# M031AE_v1 register map
File version: 1.0
Registers are 32-bit, read-write, reset 0x0 unless marked. A register's access mark holds for its fields unless they carry their own. Offsets are from the block's base; [hi:lo] are bit positions; {n}, {i} and the like mark numbered series; 'fields as' and 'values as' point back to an identical list.

## ACMP01 — ACMP Register Map
Base 0x40045000
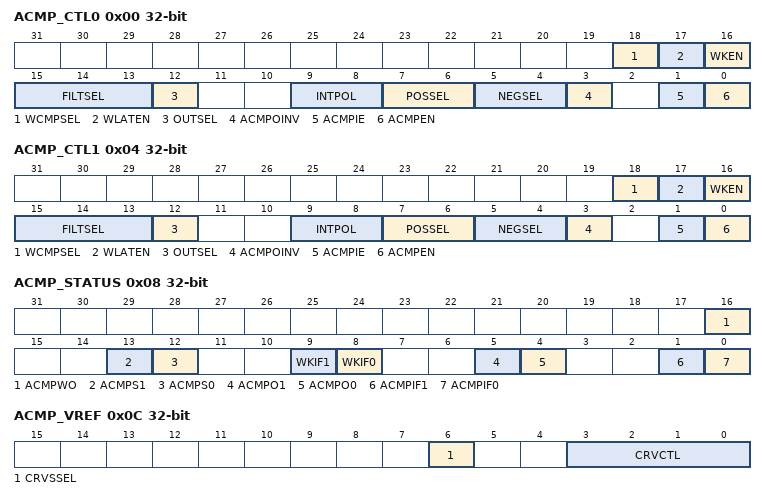
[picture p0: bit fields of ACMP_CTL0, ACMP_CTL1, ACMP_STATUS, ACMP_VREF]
0x00 ACMP_CTL0 — Analog Comparator 0 Control Register
  [18] WCMPSEL — Window Compare Mode Selection
    0=Window Compare Mode Disabled; 1=Window Compare Mode Selected
  [17] WLATEN — Window Latch Mode Enable Bit
    0=Window Latch Mode Disabled; 1=Window Latch Mode Enabled
  [16] WKEN — Power-down Wake-up Enable Bit
    0=Wake-up function Disabled; 1=Wake-up function Enabled
  [15:13] FILTSEL — Comparator Output Filter Count Selection
    0=Filter function is Disabled; 1=ACMP0 output is sampled 1 consecutive PCLK; 2=ACMP0 output is sampled 2 consecutive PCLKs; 3=ACMP0 output is sampled 4 consecutive PCLKs; 4=ACMP0 output is sampled 8 consecutive PCLKs; 5=ACMP0 output is sampled 16 consecutive PCLKs; 6=ACMP0 output is sampled 32 consecutive PCLKs; 7=ACMP0 output is sampled 64 consecutive PCLKs
  [12] OUTSEL — Comparator Output Select
    0=Comparator 0 output to ACMP0_O pin is unfiltered comparator output; 1=Comparator 0 output to ACMP0_O pin is from filter output
  [9:8] INTPOL — Interrupt Condition Polarity Selection. ACMPIF0 will be set to 1 when comparator output edge condition is detected.
    0=Rising edge or falling edge; 1=Rising edge; 2=Falling edge
  [7:6] POSSEL — Comparator Positive Input Selection
    {v}=Input from ACMP0_P{v} (v=0..3)
  [5:4] NEGSEL — Comparator Negative Input Selection
    0=ACMP0_N pin; 1=Internal comparator reference voltage (CRV); 2=Band-gap voltage
  [3] ACMPOINV — Comparator Output Inverse
    0=Comparator 0 output inverse Disabled; 1=Comparator 0 output inverse Enabled
  [1] ACMPIE — Comparator Interrupt Enable Bit
    0=Comparator 0 interrupt Disabled; 1=Comparator 0 interrupt Enabled. If WKEN (ACMP_CTL0[16]) is set to 1, the wake-up interrupt function will be enabled as well
  [0] ACMPEN — Comparator Enable Bit
    0=Comparator 0 Disabled; 1=Comparator 0 Enabled
0x04 ACMP_CTL1 — Analog Comparator 1 Control Register
  [18] WCMPSEL — Window Compare Mode Selection
    values as ACMP_CTL0.WCMPSEL
  [17] WLATEN — Window Latch Mode Enable Bit
    0=Window Latch Mode Disabled; 1=Window Latch Mode Enabled
  [16] WKEN — Power-down Wakeup Enable Bit
    0=Wake-up function Disabled; 1=Wake-up function Enabled
  [15:13] FILTSEL — Comparator Output Filter Count Selection
    0=Filter function is Disabled; 1=ACMP1 output is sampled 1 consecutive PCLK; 2=ACMP1 output is sampled 2 consecutive PCLKs; 3=ACMP1 output is sampled 4 consecutive PCLKs; 4=ACMP1 output is sampled 8 consecutive PCLKs; 5=ACMP1 output is sampled 16 consecutive PCLKs; 6=ACMP1 output is sampled 32 consecutive PCLKs; 7=ACMP1 output is sampled 64 consecutive PCLKs
  [12] OUTSEL — Comparator Output Select
    0=Comparator 1 output to ACMP1_O pin is unfiltered comparator output; 1=Comparator 1 output to ACMP1_O pin is from filter output
  [9:8] INTPOL — Interrupt Condition Polarity Selection. ACMPIF1 will be set to 1 when comparator output edge condition is detected.
    0=Rising edge or falling edge; 1=Rising edge; 2=Falling edge
  [7:6] POSSEL — Comparator Positive Input Selection
    {v}=Input from ACMP1_P{v} (v=0..3)
  [5:4] NEGSEL — Comparator Negative Input Selection
    0=ACMP1_N pin; 1=Internal comparator reference voltage (CRV); 2=Band-gap voltage
  [3] ACMPOINV — Comparator Output Inverse Control
    0=Comparator 1 output inverse Disabled; 1=Comparator 1 output inverse Enabled
  [1] ACMPIE — Comparator Interrupt Enable Bit
    0=Comparator 1 interrupt Disabled; 1=Comparator 1 interrupt Enabled. If WKEN (ACMP_CTL1[16]) is set to 1, the wake-up interrupt function will be enabled as well
  [0] ACMPEN — Comparator Enable Bit
    0=Comparator 1 Disabled; 1=Comparator 1 Enabled
0x08 ACMP_STATUS — Analog Comparator Status Register
  [16] ACMPWO — Comparator Window Output. This bit shows the output status of window compare mode
    0=The positive input voltage is outside the window; 1=The positive input voltage is in the window
  [13] ACMPS1 — Comparator 1 Status. Synchronized to the PCLK to allow reading by software. Cleared when the comparator 1 is disabled, i.e. ACMPEN (ACMP_CTL1[0]) is cleared to 0.
  [12] ACMPS0 — Comparator 0 Status. Synchronized to the PCLK to allow reading by software. Cleared when the comparator 0 is disabled, i.e. ACMPEN (ACMP_CTL0[0]) is cleared to 0.
  [9] WKIF1 — Comparator 1 Power-down Wake-up Interrupt Flag. This bit will be set to 1 when ACMP1 wake-up interrupt event occurs. Note: Write 1 to clear this bit to 0.
    0=No power-down wake-up occurred; 1=Power-down wake-up occurred
  [8] WKIF0 — Comparator 0 Power-down Wake-up Interrupt Flag. This bit will be set to 1 when ACMP0 wake-up interrupt event occurs. Note: Write 1 to clear this bit to 0.
    values as WKIF1
  [5] ACMPO1 — Comparator 1 Output. Synchronized to the PCLK to allow reading by software. Cleared when the comparator 1 is disabled, i.e. ACMPEN (ACMP_CTL1[0]) is cleared to 0.
  [4] ACMPO0 — Comparator 0 Output. Synchronized to the PCLK to allow reading by software. Cleared when the comparator 0 is disabled, i.e. ACMPEN (ACMP_CTL0[0]) is cleared to 0.
  [1] ACMPIF1 — Comparator 1 Interrupt Flag. This bit is set by hardware when the edge condition defined by INTPOL (ACMP_CTL1[9:8]) is detected on comparator 1 output. This will cause an interrupt if ACMPIE (ACMP_CTL1[1]) is set to 1. Note: Write 1 to clear this bit to 0.
  [0] ACMPIF0 — Comparator 0 Interrupt Flag. This bit is set by hardware when the edge condition defined by INTPOL (ACMP_CTL0[9:8]) is detected on comparator 0 output. This will generate an interrupt if ACMPIE (ACMP_CTL0[1]) is set to 1. Note: Write 1 to clear this bit to 0.
0x0C ACMP_VREF — Analog Comparator Reference Voltage Control Register
  [6] CRVSSEL — CRV Source Voltage Selection
    0=AVDD is selected as CRV source voltage; 1=VREF is selected as as CRV source voltage
  [3:0] CRVCTL — Comparator Reference Voltage Setting
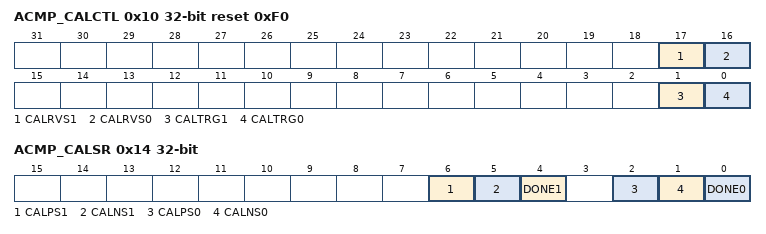
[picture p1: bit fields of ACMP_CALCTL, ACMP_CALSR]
0x10 ACMP_CALCTL reset 0xF0 — Analog Comparator Calibration Control Register
  [17] CALRVS1 — OPA1 Calibration Reference Voltage Selection. Note: CALRVS0 and CALRVS1 must be the same setting in calibration
    0=VREF is; 1=VREF from high vcm to low vcm
  [16] CALRVS0 — OPA0 Calibration Reference Voltage Selection. Note: CALRVS0 and CALRVS1 must be the same setting in calibration
    0=VREF is; 1=VREF from high vcm to low vcm
  [1] CALTRG1 — OP Amplifier 1 Calibration Trigger Bit. Note 1: Before this bit is enabled, ACMPEN(ACMP_CTL1) should be set and the internal high speed RC oscillator (HIRC) should be enabled in advance. Note 2: Hardware will auto clear this bit when next calibration is triggered by software. Note 3: If user must trigger calibration twice or more times, the second trigger have to wait at least 300us after the previous calibration done
    0=Calibration is stopped; 1=Calibration is triggered
  [0] CALTRG0 — OP Amplifier 0 Calibration Trigger Bit. Note 1: Before this bit is enabled,ACMPEN(ACMP_CTL0) should be set and the internal high speed RC oscillator (HIRC) should be enabled in advance. Note 2: Hardware will auto clear this bit when next calibration is triggered by software. Note 3: If user must trigger calibration twice or more times, the second trigger have to wait at least 300us after the previous calibration done
    0=Calibration is stopped; 1=Calibration is triggered
0x14 ACMP_CALSR ro — Analog Comparator Calibration Status Register
  [6] CALPS1 — Comparator1 Calibration Result Status for PMOS
    0=Pass; 1=Fail
  [5] CALNS1 — Comparator1 Calibration Result Status for NMOS
    0=Pass; 1=Fail
  [4] DONE1 — Comparator1 Calibration Done Status
    0=Calibrating; 1=Calibration Done
  [2] CALPS0 — Comparator0 Calibration Result Status for PMOS
    0=Pass; 1=Fail
  [1] CALNS0 — Comparator0 Calibration Result Status for NMOS
    0=Pass; 1=Fail
  [0] DONE0 — Comparator0 Calibration Done Status
    0=Calibrating; 1=Calibration Done
